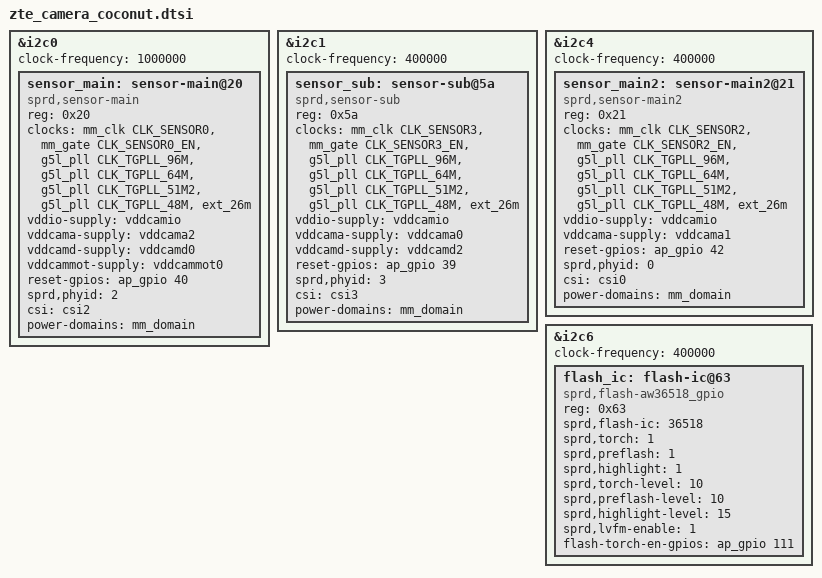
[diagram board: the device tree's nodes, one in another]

&i2c0 {
	status = "okay";
	clock-frequency = <1000000>;
	#address-cells = <1>;
	#size-cells = <0>;

	sensor_main: sensor-main@20 {
		compatible = "sprd,sensor-main";
		reg = <0x20>;
		clock-names = "clk_src","sensor_eb",
			"clk_96m","clk_64m",
			"clk_51m2","clk_48m","clk_26m";
		clocks = <&mm_clk CLK_SENSOR0>,<&mm_gate CLK_SENSOR0_EN>,
				<&g5l_pll CLK_TGPLL_96M>,<&g5l_pll CLK_TGPLL_64M>,
				<&g5l_pll CLK_TGPLL_51M2>,<&g5l_pll CLK_TGPLL_48M>,<&ext_26m>;
		vddio-supply = <&vddcamio>;
		vddcama-supply = <&vddcama2>;
		vddcamd-supply = <&vddcamd0>;
		vddcammot-supply = <&vddcammot0>;
		reset-gpios = <&ap_gpio 40 0>;
		sprd,phyid = <2>;
		csi = <&csi2>;
		power-domains = <&mm_domain>;
	};
};

&i2c1 {
	status = "okay";
	clock-frequency = <400000>;
	#address-cells = <1>;
	#size-cells = <0>;

	sensor_sub: sensor-sub@5a {
		compatible = "sprd,sensor-sub";
		reg = <0x5a>;
		clock-names = "clk_src","sensor_eb",
			"clk_96m","clk_64m",
			"clk_51m2","clk_48m","clk_26m";
		clocks = <&mm_clk CLK_SENSOR3>,<&mm_gate CLK_SENSOR3_EN>,
			<&g5l_pll CLK_TGPLL_96M>,<&g5l_pll CLK_TGPLL_64M>,
			<&g5l_pll CLK_TGPLL_51M2>,<&g5l_pll CLK_TGPLL_48M>,<&ext_26m>;
		vddio-supply = <&vddcamio>;
		vddcama-supply = <&vddcama0>;
		vddcamd-supply = <&vddcamd2>;
		reset-gpios = <&ap_gpio 39 0>;
		sprd,phyid = <3>;
		csi = <&csi3>;
		power-domains = <&mm_domain>;
	};
};

&i2c4 {
	status = "okay";
	clock-frequency = <400000>;
	#address-cells = <1>;
	#size-cells = <0>;

	sensor_main2: sensor-main2@21 {
		compatible = "sprd,sensor-main2";
		reg = <0x21>;
		clock-names = "clk_src","sensor_eb",
			"clk_96m","clk_64m",
			"clk_51m2","clk_48m","clk_26m";
		clocks = <&mm_clk CLK_SENSOR2>,<&mm_gate CLK_SENSOR2_EN>,
			<&g5l_pll CLK_TGPLL_96M>,<&g5l_pll CLK_TGPLL_64M>,
			<&g5l_pll CLK_TGPLL_51M2>,<&g5l_pll CLK_TGPLL_48M>,<&ext_26m>;
		vddio-supply = <&vddcamio>;
		vddcama-supply = <&vddcama1>;
		/*vddcamd-supply = <&vddcamio>;*/
		reset-gpios = <&ap_gpio 42 0>;
		sprd,phyid = <0>;
		csi = <&csi0>;
		power-domains = <&mm_domain>;
	};
};

&i2c6 {
	status = "okay";
	clock-frequency = <400000>;
	#address-cells = <1>;
	#size-cells = <0>;

	flash_ic: flash-ic@63 {
		compatible = "sprd,flash-aw36518_gpio";
		reg = <0x63>;
		sprd,flash-ic = <36518>;
		sprd,torch = <1>;
		sprd,preflash = <1>;
		sprd,highlight = <1>;
		sprd,torch-level = <10>;
		sprd,preflash-level = <10>;
		sprd,highlight-level = <15>;
		sprd,lvfm-enable = <1>;
		flash-torch-en-gpios  = <&ap_gpio 111 0>;
	};
};
